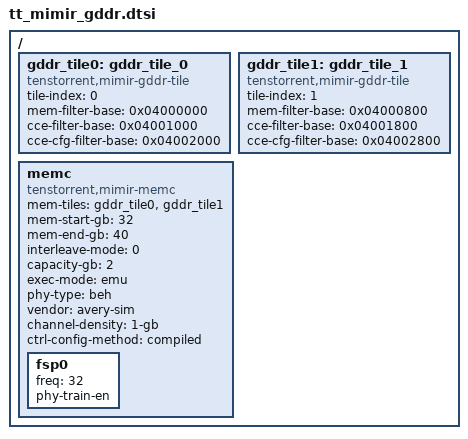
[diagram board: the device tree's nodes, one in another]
/*
 * Copyright (c) 2026 Tenstorrent AI ULC
 *
 * SPDX-License-Identifier: Apache-2.0
 */

/ {
	/* GDDR7 tiles */
	gddr_tile0: gddr_tile_0 {
		compatible = "tenstorrent,mimir-gddr-tile";
		tile-index = <0>;
		mem-filter-base = <0x04000000>;
		cce-filter-base = <0x04001000>;
		cce-cfg-filter-base = <0x04002000>;
		status = "okay";
	};

	gddr_tile1: gddr_tile_1 {
		compatible = "tenstorrent,mimir-gddr-tile";
		tile-index = <1>;
		mem-filter-base = <0x04000800>;
		cce-filter-base = <0x04001800>;
		cce-cfg-filter-base = <0x04002800>;
		status = "okay";
	};

	/* GDDR7 memory controller: brings up the tiles referenced by mem-tiles. */
	memc: memc {
		compatible = "tenstorrent,mimir-memc";
		mem-tiles = <&gddr_tile0 &gddr_tile1>;
		/* 8 GB GDDR window at the GDDR base (32 GB = 0x8_0000_0000) */
		mem-start-gb = <32>;   /* 0..127, was SCRATCH_07[6:0] */
		mem-end-gb = <40>;     /* 0..127, was SCRATCH_07[13:7]; start + 8 GB */
		interleave-mode = <0>; /* NOC_INTERLEAVE_TILE, was SCRATCH_15[4:2] */
		/*
		 * Not a GB count: a noc_gddr7_realign_t code (0 = 4 GB total,
		 * 1 = 6 GB, 2 = 8 GB, ... 7 = 32 GB). Was SCRATCH_14[17:13].
		 */
		capacity-gb = <2>;     /* NOC_GDDR7_REALIGNMENT_8GB: 1 GB/channel */

		/* GDDR bring-up params (fw_params): emulation with a behavioural PHY */
		exec-mode = "emu";
		phy-type = "beh";
		vendor = "avery-sim";
		channel-density = "1-gb";
		ctrl-config-method = "compiled";
		status = "okay";

		/* Enabled FSPs, in order; unlisted FSP fields use the library default */
		fsp0 {
			freq = <32>;
			phy-train-en;
		};
	};
};
